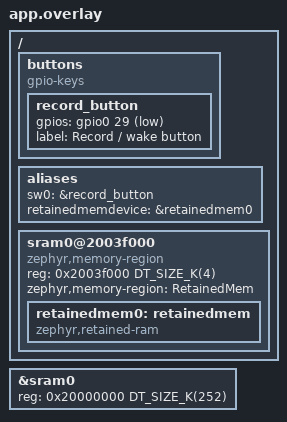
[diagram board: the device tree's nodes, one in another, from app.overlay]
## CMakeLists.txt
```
cmake_minimum_required(VERSION 3.20.0)

set(COMMON_DIR ${CMAKE_CURRENT_SOURCE_DIR}/../common)
list(APPEND DTS_ROOT ${COMMON_DIR})

find_package(Zephyr REQUIRED HINTS $ENV{ZEPHYR_BASE})
project(sus_recorder)

target_include_directories(app PRIVATE
	${COMMON_DIR}/src
	${CMAKE_CURRENT_SOURCE_DIR}/src
)

target_sources(app PRIVATE
	${COMMON_DIR}/src/as5600.c
	${COMMON_DIR}/src/battery.c
	${COMMON_DIR}/src/board_power.c
	${COMMON_DIR}/src/flash.c
	${COMMON_DIR}/src/flash_zephyr.c
	${COMMON_DIR}/src/sensor_reader.c
	src/flash_serial.c
	src/log_id_retention.c
	src/main.c
	src/status_led.c
)

target_compile_options(app PRIVATE
	-Wextra
	-Werror
)
```

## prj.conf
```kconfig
CONFIG_GPIO=y
CONFIG_ADC=y
CONFIG_I2C=y
CONFIG_I2C_NRFX_TRANSFER_TIMEOUT=2
CONFIG_SPI=y
CONFIG_FLASH=y
CONFIG_SPI_NOR=y
CONFIG_SPI_NOR_SFDP_RUNTIME=y
CONFIG_FLASH_JESD216_API=y
CONFIG_SPI_NOR_FLASH_LAYOUT_PAGE_SIZE=4096
CONFIG_SENSOR=y

CONFIG_LSM6DSO=y
CONFIG_LSM6DSO_ENABLE_TEMP=y
CONFIG_LSM6DSO_TRIGGER_NONE=y

CONFIG_MMC56X3=y

CONFIG_LIS3MDL=y
CONFIG_LIS3MDL_ODR="155"
CONFIG_LIS3MDL_FS=8
CONFIG_LIS3MDL_TRIGGER_NONE=y

CONFIG_RETAINED_MEM=y
CONFIG_CRC=y
CONFIG_POWEROFF=y
CONFIG_PM_DEVICE=y

CONFIG_PRINTK=y
CONFIG_SERIAL=y
CONFIG_UART_INTERRUPT_DRIVEN=y
CONFIG_CONSOLE=y
CONFIG_UART_CONSOLE=y

CONFIG_MAIN_STACK_SIZE=3072
CONFIG_MAIN_THREAD_PRIORITY=5
CONFIG_ASSERT=y
```

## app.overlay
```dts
#include "../common/sus_board.dtsi"

/ {
	buttons {
		compatible = "gpio-keys";

		record_button: record_button {
			/* XIAO D3 = nRF P0.29; normally open, pressed connects to ground. */
			gpios = <&gpio0 29 (GPIO_PULL_UP | GPIO_ACTIVE_LOW)>;
			label = "Record / wake button";
		};
	};

	aliases {
		sw0 = &record_button;
		retainedmemdevice = &retainedmem0;
	};

	/*
	 * Retain one 4 KiB nRF52840 RAM section across System OFF. The normal
	 * SRAM node below is shortened so the linker cannot use this region.
	 */
	sram0@2003f000 {
		compatible = "zephyr,memory-region", "mmio-sram";
		reg = <0x2003f000 DT_SIZE_K(4)>;
		zephyr,memory-region = "RetainedMem";
		status = "okay";

		retainedmem0: retainedmem {
			compatible = "zephyr,retained-ram";
			status = "okay";
		};
	};
};

&sram0 {
	reg = <0x20000000 DT_SIZE_K(252)>;
};
```

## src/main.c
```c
#include <errno.h>
#include <stdbool.h>
#include <stddef.h>
#include <stdint.h>
#include <string.h>

#include <zephyr/device.h>
#include <zephyr/devicetree.h>
#include <zephyr/drivers/gpio.h>
#include <zephyr/drivers/usb/udc.h>
#include <zephyr/kernel.h>
#include <zephyr/pm/device.h>
#include <zephyr/sys/atomic.h>
#include <zephyr/sys/poweroff.h>
#include <zephyr/sys/printk.h>
#include <zephyr/sys/util.h>

#include "as5600.h"
#include "battery.h"
#include "board_power.h"
#include "flash.h"
#include "flash_serial.h"
#include "flash_zephyr.h"
#include "log_id_retention.h"
#include "log_record.h"
#include "sensor_reader.h"
#include "status_led.h"

#define SAMPLE_INTERVAL_MS 5U
#define BUTTON_POLL_MS 20U
#define BUTTON_DEBOUNCE_MS 50U
#define BUTTON_LONG_PRESS_MS 800U
#define UPLOAD_HELLO_WINDOW_MS 5000U
#define RECORD_QUEUE_DEPTH 128U
#define FLASH_SCAN_STATUS_INTERVAL_SECTORS 256U
#define FLASH_SCAN_STATUS_INTERVAL_MS 5000U
#define REQUIRED_SENSOR_MASK \
	(SUS_SENSOR_IMU1 | SUS_SENSOR_IMU2 | SUS_SENSOR_MMC5603)
#define RECORDS_PER_SECTOR \
	(FLASH_LOG_PAYLOAD_BYTES / sizeof(struct sus_log_record))

BUILD_ASSERT(RECORDS_PER_SECTOR == 81U);

K_MSGQ_DEFINE(record_queue, sizeof(struct sus_log_record),
	      RECORD_QUEUE_DEPTH, 4);
K_SEM_DEFINE(sampler_stopped, 0, 1);

static const struct gpio_dt_spec record_button =
	GPIO_DT_SPEC_GET(DT_ALIAS(sw0), gpios);
static const struct device *const usb_controller =
	DEVICE_DT_GET(DT_NODELABEL(zephyr_udc0));
static const struct device *const serial_uart =
	DEVICE_DT_GET(DT_CHOSEN(zephyr_console));

static struct sus_sensor_reader sensor_reader;
static struct sus_as5600 angle_sensor;
static atomic_t stop_requested;
static atomic_t dropped_records;
static atomic_t missed_deadlines;
static atomic_t angle_read_errors;
static atomic_t sensor_fault_detected;
static bool record_button_ready;

struct flash_scan_status {
	int64_t started_ms;
	int64_t last_report_ms;
	uint32_t erased_sectors;
	bool erase_pending;
};

static void flash_scan_progress(void *context,
				enum flash_log_scan_phase phase,
				uint32_t completed_sectors,
				uint32_t total_sectors)
{
	struct flash_scan_status *status = context;
	int64_t now = k_uptime_get();
	uint32_t elapsed_seconds;
	uint32_t percent;
	bool report_due;

	if (phase == FLASH_LOG_SCAN_CLEANUP_ERASE) {
		status->erase_pending = true;
		if (status->erased_sectors != 0U &&
		    now - status->last_report_ms <
			    FLASH_SCAN_STATUS_INTERVAL_MS) {
			return;
		}
		elapsed_seconds = (uint32_t)((now - status->started_ms) /
					     1000);
		printk("Flash scan cleanup: starting erase %u after "
		       "%u/%u inspected, elapsed=%u s\n",
		       status->erased_sectors + 1U, completed_sectors,
		       total_sectors, elapsed_seconds);
		status->last_report_ms = now;
		return;
	}

	if (phase == FLASH_LOG_SCAN_CLEANUP && status->erase_pending) {
		status->erased_sectors++;
		status->erase_pending = false;
	}
	if (completed_sectors == 0U || total_sectors == 0U) {
		return;
	}

	report_due = completed_sectors == total_sectors ||
		     (completed_sectors %
		      FLASH_SCAN_STATUS_INTERVAL_SECTORS) == 0U ||
		     now - status->last_report_ms >=
			     FLASH_SCAN_STATUS_INTERVAL_MS;
	if (!report_due) {
		return;
	}

	elapsed_seconds = (uint32_t)((now - status->started_ms) / 1000);
	percent = (completed_sectors * 100U) / total_sectors;
	if (phase == FLASH_LOG_SCAN_DISCOVER) {
		printk("Flash scan discover: %u/%u inspected (%u%%), "
		       "elapsed=%u s\n",
		       completed_sectors, total_sectors, percent,
		       elapsed_seconds);
	} else {
		printk("Flash scan cleanup: %u/%u inspected (%u%%), "
		       "erased=%u, elapsed=%u s\n",
		       completed_sectors, total_sectors, percent,
		       status->erased_sectors, elapsed_seconds);
	}
	status->last_report_ms = now;
}

static void make_record(struct sus_log_record *record)
{
	struct sus_sensor_sample sample;
	uint16_t angle;

	sus_sensor_reader_read(&sensor_reader, &sample);
	if ((sample.valid & REQUIRED_SENSOR_MASK) != REQUIRED_SENSOR_MASK) {
		atomic_set(&sensor_fault_detected, 1);
	}
	memset(record, 0, sizeof(*record));
	record->timestamp_ms = sample.timestamp_ms;
	record->sequence = sample.sequence;
	memcpy(record->imu1_accel_mg, sample.imu1.accel_mg,
	       sizeof(record->imu1_accel_mg));
	memcpy(record->imu2_accel_mg, sample.imu2.accel_mg,
	       sizeof(record->imu2_accel_mg));
	memcpy(record->imu1_gyro_dps10, sample.imu1.gyro_dps10,
	       sizeof(record->imu1_gyro_dps10));
	memcpy(record->imu2_gyro_dps10, sample.imu2.gyro_dps10,
	       sizeof(record->imu2_gyro_dps10));
	memcpy(record->mmc5603_mg, sample.mmc5603_mg,
	       sizeof(record->mmc5603_mg));
	memcpy(record->lis3mdl_mg, sample.lis3mdl_mg,
	       sizeof(record->lis3mdl_mg));
	record->temp_deci_c = sample.imu1.temp_deci_c;

	if (sus_as5600_read(&angle_sensor, &angle) != 0) {
		atomic_inc(&angle_read_errors);
		atomic_set(&sensor_fault_detected, 1);
	} else {
		record->angle = angle;
	}
}

static void sampler_thread(void *unused1, void *unused2, void *unused3)
{
	int64_t deadline = k_uptime_get();

	ARG_UNUSED(unused1);
	ARG_UNUSED(unused2);
	ARG_UNUSED(unused3);

	while (atomic_get(&stop_requested) == 0) {
		struct sus_log_record record;
		int64_t now;

		deadline += SAMPLE_INTERVAL_MS;
		k_sleep(K_TIMEOUT_ABS_MS(deadline));
		if (atomic_get(&stop_requested) != 0) {
			break;
		}

		make_record(&record);
		if (k_msgq_put(&record_queue, &record, K_NO_WAIT) != 0) {
			atomic_inc(&dropped_records);
		}

		now = k_uptime_get();
		if (now >= deadline + SAMPLE_INTERVAL_MS) {
			int64_t skipped =
				(now - deadline) / SAMPLE_INTERVAL_MS;

			deadline += skipped * SAMPLE_INTERVAL_MS;
			atomic_add(&missed_deadlines, (atomic_val_t)skipped);
		}
	}

	k_sem_give(&sampler_stopped);
}

static void button_thread(void *unused1, void *unused2, void *unused3)
{
	int64_t pressed_at = 0;

	ARG_UNUSED(unused1);
	ARG_UNUSED(unused2);
	ARG_UNUSED(unused3);

	/* Do not count the button press that woke the board as a stop press. */
	while (gpio_pin_get_dt(&record_button) > 0) {
		k_msleep(BUTTON_POLL_MS);
	}
	k_msleep(BUTTON_DEBOUNCE_MS);

	while (atomic_get(&stop_requested) == 0) {
		int pressed = gpio_pin_get_dt(&record_button);

		if (pressed > 0) {
			if (pressed_at == 0) {
				pressed_at = k_uptime_get();
			} else if (k_uptime_get() - pressed_at >=
				   BUTTON_LONG_PRESS_MS) {
				atomic_set(&stop_requested, 1);
				status_led_set(STATUS_LED_OFF);
				printk("Long press: stopping recording\n");
				break;
			}
		} else {
			pressed_at = 0;
		}
		k_msleep(BUTTON_POLL_MS);
	}
}

K_THREAD_DEFINE(sampler_thread_id, 3072, sampler_thread,
		NULL, NULL, NULL, 1, 0, SYS_FOREVER_MS);
K_THREAD_DEFINE(button_thread_id, 1024, button_thread,
		NULL, NULL, NULL, 2, 0, SYS_FOREVER_MS);

struct record_accumulator {
	struct sus_log_record records[RECORDS_PER_SECTOR];
	size_t count;
};

static enum flash_log_result
flush_records(struct flash_log *log, struct record_accumulator *accumulator,
	      uint32_t *written_records)
{
	enum flash_log_result result;

	if (accumulator->count == 0U) {
		return FLASH_LOG_OK;
	}

	result = flash_log_append(
		log, accumulator->records,
		accumulator->count * sizeof(accumulator->records[0]));
	if (result == FLASH_LOG_OK) {
		*written_records += (uint32_t)accumulator->count;
		accumulator->count = 0U;
	}
	return result;
}

static enum flash_log_result
queue_record(struct flash_log *log, struct record_accumulator *accumulator,
	     const struct sus_log_record *record, uint32_t *written_records)
{
	accumulator->records[accumulator->count++] = *record;
	if (accumulator->count == ARRAY_SIZE(accumulator->records)) {
		return flush_records(log, accumulator, written_records);
	}
	return FLASH_LOG_OK;
}

static void wait_for_button_release(void)
{
	while (gpio_pin_get_dt(&record_button) > 0) {
		k_msleep(BUTTON_POLL_MS);
	}
	k_msleep(BUTTON_DEBOUNCE_MS);
}

static void enter_system_off(struct flash_zephyr_storage *storage)
{
	int err;

	if (!record_button_ready) {
		printk("Cannot enter System OFF without a configured wake button\n");
		return;
	}

	if (storage != NULL && storage->device != NULL) {
		err = pm_device_action_run(storage->device,
					   PM_DEVICE_ACTION_SUSPEND);
		if (err != 0 && err != -EALREADY) {
			printk("Flash deep-power-down failed: %d\n", err);
		}
		k_msleep(1);
	}

	err = board_peripheral_power_set_enabled(false);
	if (err != 0) {
		printk("Peripheral rail shutdown failed: %d\n", err);
	}

	/* Hardware is quiescent; only now wait for a clean wake-button edge. */
	wait_for_button_release();

	err = gpio_pin_interrupt_configure_dt(&record_button,
					      GPIO_INT_LEVEL_ACTIVE);
	if (err != 0) {
		printk("Button wake configuration failed: %d\n", err);
		return;
	}

	printk("Entering System OFF; press D3 to record again\n");
	k_msleep(10);

	if (device_is_ready(usb_controller)) {
		(void)udc_disable(usb_controller);
	}
	status_led_set(STATUS_LED_OFF);
	sys_poweroff();
}

static void indicate_error(void)
{
	status_led_set(STATUS_LED_RED);
	/* Keep fatal errors visible before System OFF removes LED power. */
	k_msleep(1500);
}

static int retain_log_state(const struct flash_log *log, bool clean)
{
	struct flash_log_checkpoint checkpoint;

	flash_log_checkpoint_save(log, &checkpoint);
	return log_id_retention_store(&checkpoint, clean);
}

static int recorder_hardware_init(void)
{
	int err;

	if (!gpio_is_ready_dt(&record_button)) {
		return -ENODEV;
	}

	err = gpio_pin_configure_dt(&record_button, GPIO_INPUT);
	if (err != 0) {
		return err;
	}
	record_button_ready = true;
	if (!board_peripheral_power_is_ready()) {
		return -ENODEV;
	}

	sus_sensor_reader_init(&sensor_reader);
	err = sus_as5600_init(&angle_sensor);
	if (err != 0) {
		printk("AS5600 not available: %d; angle will be zero\n", err);
	}

	printk("Sensors: IMU1=%s IMU2=%s MMC5603=%s LIS3MDL=%s "
	       "AS5600=%s\n",
	       (sensor_reader.available & SUS_SENSOR_IMU1) != 0U ?
		       "yes" : "no",
	       (sensor_reader.available & SUS_SENSOR_IMU2) != 0U ?
		       "yes" : "no",
	       (sensor_reader.available & SUS_SENSOR_MMC5603) != 0U ?
		       "yes" : "no",
	       (sensor_reader.available & SUS_SENSOR_LIS3MDL) != 0U ?
		       "yes" : "no",
	       angle_sensor.available ? "yes" : "no");
	return 0;
}

int main(void)
{
	static struct flash_zephyr_storage storage;
	static struct flash_chunk scratch;
	static struct flash_log log;
	static struct flash_serial_transport serial_transport;
	static struct record_accumulator accumulator;
	struct sus_log_record record;
	struct retained_log_state retained_state;
	struct flash_scan_status scan_status;
	enum flash_log_result log_result;
	uint32_t active_log_id = 0;
	uint32_t written_records = 0;
	int64_t next_status_ms;
	enum flash_serial_session_result upload_result;
	const struct flash_transport_ops *transport_ops = NULL;
	void *transport_context = NULL;
	bool writer_ok = true;
	bool serial_ready = false;
	bool retained_state_available = false;
	bool checkpoint_restored = false;
	bool recording_error = false;
	int32_t battery_mv;
	int err;

	printk("\nSUS 200 Hz recorder starting\n");
	err = sus_battery_init();
	if (err != 0) {
		printk("Battery monitor initialization failed: %d\n", err);
	} else {
		err = sus_battery_read_mv(&battery_mv);
		if (err != 0) {
			printk("Battery voltage read failed: %d\n", err);
		} else {
			printk("Battery: %d mV\n", battery_mv);
		}
	}
	err = status_led_init();
	if (err != 0) {
		printk("Status LED unavailable: %d\n", err);
	} else {
		status_led_set(STATUS_LED_WHITE);
	}

	err = recorder_hardware_init();
	if (err != 0) {
		printk("Hardware initialization failed: %d\n", err);
		indicate_error();
		enter_system_off(NULL);
		return 0;
	}

	err = flash_zephyr_storage_init_default(&storage);
	if (err != 0) {
		printk("Flash initialization failed: %d\n", err);
		indicate_error();
		enter_system_off(&storage);
		return 0;
	}

	err = flash_serial_transport_init(
		&serial_transport, serial_uart, storage.sector_count);
	if (err == 0) {
		transport_ops = &flash_serial_transport_ops;
		transport_context = &serial_transport;
		serial_ready = true;
	} else {
		printk("USB log upload unavailable: %d\n", err);
	}

	log_result = flash_log_init(
		&log, storage.sector_count, &scratch,
		&flash_zephyr_storage_ops, &storage, transport_ops,
		transport_context);
	if (log_result != FLASH_LOG_OK) {
		printk("Flash log initialization failed: %d\n", log_result);
		indicate_error();
		enter_system_off(&storage);
		return 0;
	}

	err = log_id_retention_load(&retained_state);
	if (err == 0) {
		retained_state_available = true;
		if (retained_state.clean) {
			log_result = flash_log_checkpoint_restore(
				&log, &retained_state.checkpoint);
			if (log_result == FLASH_LOG_OK) {
				checkpoint_restored = true;
				printk("Restored flash checkpoint: read=%u "
				       "write=%u next_log=%u\n",
				       log.read_sector, log.write_sector,
				       log.next_log_id);
			} else {
				printk("Retained flash checkpoint rejected: %d\n",
				       log_result);
			}
		} else {
			printk("Retained flash checkpoint is dirty; "
			       "full scan required\n");
		}
	} else {
		printk("Retained flash checkpoint unavailable: %d; "
		       "full scan required\n", err);
	}

	if (!checkpoint_restored) {
		status_led_set(STATUS_LED_PURPLE);
		scan_status = (struct flash_scan_status) {
			.started_ms = k_uptime_get(),
			.last_report_ms = k_uptime_get(),
		};
		printk("Scanning %u flash sectors...\n", log.sector_count);
		log_result = flash_log_scan_with_progress(
			&log, flash_scan_progress, &scan_status);
		if (log_result != FLASH_LOG_OK) {
			printk("Flash scan failed: %d\n", log_result);
			indicate_error();
			enter_system_off(&storage);
			return 0;
		}

		if (flash_log_is_empty(&log) && retained_state_available) {
			log.next_log_id =
				retained_state.checkpoint.next_log_id;
			printk("Restored next log ID %u from retained RAM\n",
			       log.next_log_id);
		} else if (!flash_log_is_empty(&log)) {
			printk("Recovered next log ID %u from flash\n",
			       log.next_log_id);
		} else {
			printk("No retained log ID; starting at %u\n",
			       log.next_log_id);
		}
	}

	/* Any flash mutation makes these pointers unsafe until re-checkpointed. */
	err = retain_log_state(&log, false);
	if (err != 0) {
		printk("Could not invalidate retained flash checkpoint: %d\n",
		       err);
		indicate_error();
		enter_system_off(&storage);
		return 0;
	}

	if (serial_ready) {
		status_led_set(STATUS_LED_BLUE);
		printk("Waiting %u ms for a USB log receiver...\n",
		       UPLOAD_HELLO_WINDOW_MS);
		upload_result = flash_serial_upload_session(
			&serial_transport, &log,
			UPLOAD_HELLO_WINDOW_MS);
		if (upload_result != FLASH_SERIAL_NO_HOST) {
			if (upload_result == FLASH_SERIAL_SESSION_COMPLETE) {
				err = retain_log_state(&log, true);
				if (err != 0) {
					printk("Post-upload checkpoint failed: %d\n",
					       err);
					indicate_error();
				}
			} else {
				indicate_error();
			}
			printk("USB upload session %s; powering down\n",
			       upload_result ==
					       FLASH_SERIAL_SESSION_COMPLETE ?
				       "complete" : "failed");
			enter_system_off(&storage);
			return 0;
		}
	}

	log_result = flash_log_begin(&log, &active_log_id);
	if (log_result != FLASH_LOG_OK) {
		printk("Could not begin log: %d\n", log_result);
		indicate_error();
		enter_system_off(&storage);
		return 0;
	}

	printk("Recording log %u at 200 Hz; hold D3 for 0.8 s to stop\n",
	       active_log_id);
	if ((sensor_reader.available & REQUIRED_SENSOR_MASK) ==
			REQUIRED_SENSOR_MASK && angle_sensor.available) {
		status_led_set(STATUS_LED_GREEN);
	} else {
		atomic_set(&sensor_fault_detected, 1);
		status_led_set(STATUS_LED_YELLOW);
	}
	k_thread_start(sampler_thread_id);
	k_thread_start(button_thread_id);
	next_status_ms = k_uptime_get() + 1000;

	while (atomic_get(&stop_requested) == 0) {
		if (k_msgq_get(&record_queue, &record, K_MSEC(100)) == 0) {
			log_result = queue_record(
				&log, &accumulator, &record,
				&written_records);
			if (log_result != FLASH_LOG_OK) {
				printk("Flash append stopped: %d\n",
				       log_result);
				status_led_set(STATUS_LED_RED);
				recording_error = true;
				writer_ok = false;
				atomic_set(&stop_requested, 1);
				break;
			}
		}

		if (k_uptime_get() >= next_status_ms) {
			if ((atomic_get(&sensor_fault_detected) != 0 ||
			     atomic_get(&dropped_records) != 0 ||
			     atomic_get(&missed_deadlines) != 0) && writer_ok) {
				status_led_set(STATUS_LED_YELLOW);
			}
			printk("log=%u records=%u queued=%u dropped=%ld "
			       "missed=%ld\n",
			       active_log_id, written_records,
			       k_msgq_num_used_get(&record_queue),
			       (long)atomic_get(&dropped_records),
			       (long)atomic_get(&missed_deadlines));
			next_status_ms += 1000;
		}
	}

	k_sem_take(&sampler_stopped, K_FOREVER);
	while (k_msgq_get(&record_queue, &record, K_NO_WAIT) == 0) {
		if (writer_ok) {
			log_result = queue_record(
				&log, &accumulator, &record,
				&written_records);
			if (log_result != FLASH_LOG_OK) {
				printk("Final flash append failed: %d\n",
				       log_result);
				status_led_set(STATUS_LED_RED);
				recording_error = true;
				writer_ok = false;
			}
		}
	}

	if (writer_ok) {
		log_result = flush_records(&log, &accumulator,
					   &written_records);
		if (log_result != FLASH_LOG_OK) {
			printk("Partial-sector write failed: %d\n",
			       log_result);
			status_led_set(STATUS_LED_RED);
			recording_error = true;
			writer_ok = false;
		}
	}

	log_result = flash_log_close(&log);
	if (log_result != FLASH_LOG_OK) {
		status_led_set(STATUS_LED_RED);
		recording_error = true;
		printk("Commit write failed: %d; boot recovery will retain "
		       "the valid prefix\n", log_result);
	} else {
		printk("Closed log %u: %u records, dropped=%ld, "
		       "missed=%ld, angle_errors=%ld%s\n",
		       active_log_id, written_records,
		       (long)atomic_get(&dropped_records),
		       (long)atomic_get(&missed_deadlines),
		       (long)atomic_get(&angle_read_errors),
		       writer_ok ? "" : " (recording stopped early)");
	}

	if (log_result == FLASH_LOG_OK) {
		err = retain_log_state(&log, true);
		if (err != 0) {
			printk("Final flash checkpoint failed: %d\n", err);
			status_led_set(STATUS_LED_RED);
			recording_error = true;
		}
	}

	if (recording_error) {
		indicate_error();
	}
	enter_system_off(&storage);
	return 0;
}
```

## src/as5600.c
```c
#include "as5600.h"

#include <errno.h>
#include <stdint.h>

#include <zephyr/device.h>
#include <zephyr/devicetree.h>
#include <zephyr/drivers/i2c.h>

#define AS5600_ADDRESS 0x36U
#define AS5600_ZPOS_REGISTER 0x01U
#define AS5600_MPOS_REGISTER 0x03U
#define AS5600_MANG_REGISTER 0x05U
#define AS5600_CONF_REGISTER 0x07U
#define AS5600_STATUS_REGISTER 0x0bU
#define AS5600_ANGLE_REGISTER 0x0eU

#define AS5600_CONF_HIGH 0x06U
#define AS5600_CONF_LOW 0x20U

static const struct device *const sensor_i2c =
	DEVICE_DT_GET(DT_BUS(DT_ALIAS(imu1)));

static int as5600_write_u12(uint8_t reg, uint16_t value)
{
	const uint8_t bytes[2] = {
		(uint8_t)((value >> 8U) & 0x0fU),
		(uint8_t)value,
	};

	return i2c_burst_write(sensor_i2c, AS5600_ADDRESS, reg, bytes,
			       sizeof(bytes));
}

int sus_as5600_init(struct sus_as5600 *sensor)
{
	uint8_t status;
	const uint8_t config[2] = {
		AS5600_CONF_HIGH,
		AS5600_CONF_LOW,
	};
	int err;

	if (sensor == NULL || !device_is_ready(sensor_i2c)) {
		return -ENODEV;
	}

	sensor->i2c = sensor_i2c;
	sensor->available = false;

	err = i2c_reg_read_byte(sensor->i2c, AS5600_ADDRESS,
				AS5600_STATUS_REGISTER, &status);
	if (err != 0) {
		return err;
	}

	/*
	 * Match the ESP configuration: normal power, no hysteresis, digital
	 * PWM output, 4x slow filter, 6-LSB fast-filter threshold, watchdog
	 * off, and the full 12-bit angular range.
	 */
	err = i2c_burst_write(sensor->i2c, AS5600_ADDRESS,
			      AS5600_CONF_REGISTER, config,
			      sizeof(config));
	if (err == 0) {
		err = as5600_write_u12(AS5600_ZPOS_REGISTER, 0U);
	}
	if (err == 0) {
		err = as5600_write_u12(AS5600_MPOS_REGISTER, 4095U);
	}
	if (err == 0) {
		err = as5600_write_u12(AS5600_MANG_REGISTER, 4095U);
	}
	if (err != 0) {
		return err;
	}

	sensor->available = true;
	return 0;
}

int sus_as5600_read(const struct sus_as5600 *sensor, uint16_t *angle)
{
	uint8_t bytes[2];
	int err;

	if (sensor == NULL || angle == NULL || !sensor->available) {
		return -ENODEV;
	}

	err = i2c_burst_read(sensor->i2c, AS5600_ADDRESS,
			     AS5600_ANGLE_REGISTER, bytes, sizeof(bytes));
	if (err != 0) {
		return err;
	}

	*angle = (((uint16_t)bytes[0] << 8U) | bytes[1]) & 0x0fffU;
	return 0;
}
```

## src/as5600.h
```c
#ifndef SUS_AS5600_H_
#define SUS_AS5600_H_

#include <stdbool.h>
#include <stdint.h>

#include <zephyr/device.h>

struct sus_as5600 {
	const struct device *i2c;
	bool available;
};

int sus_as5600_init(struct sus_as5600 *sensor);
int sus_as5600_read(const struct sus_as5600 *sensor, uint16_t *angle);

#endif /* SUS_AS5600_H_ */
```

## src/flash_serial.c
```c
#include "flash_serial.h"

#include <errno.h>
#include <stdbool.h>
#include <stddef.h>
#include <stdint.h>
#include <string.h>

#include <zephyr/drivers/uart.h>
#include <zephyr/kernel.h>
#include <zephyr/sys/crc.h>

#define FLASH_SERIAL_MAGIC UINT32_C(0x50535553)
#define FLASH_SERIAL_HEADER_BYTES 12U
#define FLASH_SERIAL_CRC_BYTES 4U
#define FLASH_SERIAL_FRAME_TIMEOUT_MS 10000U

enum flash_serial_message {
	FLASH_SERIAL_HELLO = 1,
	FLASH_SERIAL_INFO = 2,
	FLASH_SERIAL_READ_NEXT = 3,
	FLASH_SERIAL_BEGIN = 4,
	FLASH_SERIAL_SECTOR = 5,
	FLASH_SERIAL_SECTOR_ACK = 6,
	FLASH_SERIAL_END = 7,
	FLASH_SERIAL_DISPOSITION = 8,
	FLASH_SERIAL_EMPTY = 9,
	FLASH_SERIAL_SESSION_DONE = 10,
	FLASH_SERIAL_ERROR = 11,
	FLASH_SERIAL_ERASE_COMPLETE = 12,
};

enum flash_serial_disposition {
	FLASH_SERIAL_DISPOSITION_ERASE = 1,
	FLASH_SERIAL_DISPOSITION_RETRY = 2,
	FLASH_SERIAL_DISPOSITION_DONE = 3,
};

struct flash_serial_frame {
	uint8_t type;
	uint32_t token;
	const uint8_t *payload;
	uint16_t payload_length;
};

static void store_u16_le(uint8_t output[2], uint16_t value)
{
	output[0] = (uint8_t)value;
	output[1] = (uint8_t)(value >> 8U);
}

static void store_u32_le(uint8_t output[4], uint32_t value)
{
	output[0] = (uint8_t)value;
	output[1] = (uint8_t)(value >> 8U);
	output[2] = (uint8_t)(value >> 16U);
	output[3] = (uint8_t)(value >> 24U);
}

static uint16_t load_u16_le(const uint8_t input[2])
{
	return (uint16_t)input[0] | ((uint16_t)input[1] << 8U);
}

static uint32_t load_u32_le(const uint8_t input[4])
{
	return (uint32_t)input[0] | ((uint32_t)input[1] << 8U) |
	       ((uint32_t)input[2] << 16U) |
	       ((uint32_t)input[3] << 24U);
}

static size_t cobs_encode(const uint8_t *input, size_t input_length,
			  uint8_t *output, size_t output_capacity)
{
	size_t read_index = 0;
	size_t write_index = 1;
	size_t code_index = 0;
	uint8_t code = 1;

	if (output_capacity == 0U) {
		return 0;
	}

	while (read_index < input_length) {
		if (input[read_index] == 0U) {
			if (code_index >= output_capacity) {
				return 0;
			}
			output[code_index] = code;
			code = 1;
			code_index = write_index++;
			if (write_index > output_capacity) {
				return 0;
			}
			read_index++;
			continue;
		}

		if (write_index >= output_capacity) {
			return 0;
		}
		output[write_index++] = input[read_index++];
		code++;
		if (code == UINT8_MAX) {
			if (code_index >= output_capacity) {
				return 0;
			}
			output[code_index] = code;
			code = 1;
			code_index = write_index++;
			if (write_index > output_capacity) {
				return 0;
			}
		}
	}

	if (code_index >= output_capacity) {
		return 0;
	}
	output[code_index] = code;
	return write_index;
}

static size_t cobs_decode_in_place(uint8_t *buffer, size_t encoded_length)
{
	size_t read_index = 0;
	size_t write_index = 0;

	while (read_index < encoded_length) {
		uint8_t code = buffer[read_index++];
		size_t copy_length;

		if (code == 0U) {
			return 0;
		}
		copy_length = (size_t)code - 1U;
		if (read_index + copy_length > encoded_length) {
			return 0;
		}
		for (size_t i = 0; i < copy_length; i++) {
			buffer[write_index++] = buffer[read_index++];
		}
		if (code != UINT8_MAX && read_index < encoded_length) {
			buffer[write_index++] = 0U;
		}
	}

	return write_index;
}

static void serial_uart_callback(const struct device *uart, void *user_data)
{
	struct flash_serial_transport *transport = user_data;
	unsigned char byte;

	if (uart_irq_update(uart) <= 0) {
		return;
	}

	while (uart_irq_rx_ready(uart)) {
		if (uart_fifo_read(uart, &byte, 1) <= 0) {
			break;
		}
		if (k_msgq_put(&transport->rx_queue, &byte, K_NO_WAIT) != 0) {
			atomic_set(&transport->rx_overflow, 1);
		}
	}

	if (!uart_irq_tx_ready(uart) ||
	    atomic_get(&transport->tx_active) == 0) {
		return;
	}

	while (transport->tx_offset < transport->tx_length) {
		size_t remaining =
			transport->tx_length - transport->tx_offset;
		int written = uart_fifo_fill(
			uart, &transport->tx_data[transport->tx_offset],
			(int)remaining);

		if (written <= 0) {
			break;
		}
		transport->tx_offset += (size_t)written;
	}

	if (transport->tx_offset == transport->tx_length &&
	    atomic_cas(&transport->tx_active, 1, 0)) {
		uart_irq_tx_disable(uart);
		k_sem_give(&transport->tx_done);
	}
}

static int send_encoded(struct flash_serial_transport *transport,
			size_t encoded_length)
{
	k_sem_reset(&transport->tx_done);
	transport->tx_data = transport->encoded;
	transport->tx_length = encoded_length;
	transport->tx_offset = 0;
	atomic_set(&transport->tx_active, 1);
	uart_irq_tx_enable(transport->uart);

	if (k_sem_take(&transport->tx_done,
		       K_MSEC(FLASH_SERIAL_FRAME_TIMEOUT_MS)) != 0) {
		atomic_clear(&transport->tx_active);
		uart_irq_tx_disable(transport->uart);
		return -ETIMEDOUT;
	}
	return 0;
}

static int send_frame(struct flash_serial_transport *transport,
		      uint8_t type, uint32_t token,
		      const void *payload, uint16_t payload_length)
{
	size_t decoded_length = FLASH_SERIAL_HEADER_BYTES +
				(size_t)payload_length +
				FLASH_SERIAL_CRC_BYTES;
	size_t encoded_length;
	uint32_t crc;

	if (transport == NULL || transport->uart == NULL ||
	    decoded_length > sizeof(transport->decoded) ||
	    (payload_length != 0U && payload == NULL)) {
		return -EINVAL;
	}

	store_u32_le(&transport->decoded[0], FLASH_SERIAL_MAGIC);
	transport->decoded[4] = FLASH_SERIAL_PROTOCOL_VERSION;
	transport->decoded[5] = type;
	store_u16_le(&transport->decoded[6], payload_length);
	store_u32_le(&transport->decoded[8], token);
	if (payload_length != 0U) {
		memcpy(&transport->decoded[FLASH_SERIAL_HEADER_BYTES],
		       payload, payload_length);
	}
	crc = crc32_ieee(transport->decoded,
			 decoded_length - FLASH_SERIAL_CRC_BYTES);
	store_u32_le(&transport->decoded[
			     decoded_length - FLASH_SERIAL_CRC_BYTES],
		     crc);

	transport->encoded[0] = 0U;
	encoded_length = cobs_encode(
		transport->decoded, decoded_length,
		&transport->encoded[1],
		sizeof(transport->encoded) - 2U);
	if (encoded_length == 0U) {
		return -EMSGSIZE;
	}
	transport->encoded[encoded_length + 1U] = 0U;
	return send_encoded(transport, encoded_length + 2U);
}

static bool parse_frame(struct flash_serial_transport *transport,
			size_t encoded_length,
			struct flash_serial_frame *frame)
{
	size_t decoded_length =
		cobs_decode_in_place(transport->encoded, encoded_length);
	uint16_t payload_length;
	uint32_t expected_crc;
	uint32_t actual_crc;

	if (decoded_length <
	    FLASH_SERIAL_HEADER_BYTES + FLASH_SERIAL_CRC_BYTES) {
		return false;
	}
	payload_length = load_u16_le(&transport->encoded[6]);
	if (decoded_length != FLASH_SERIAL_HEADER_BYTES +
				      (size_t)payload_length +
				      FLASH_SERIAL_CRC_BYTES ||
	    load_u32_le(&transport->encoded[0]) !=
		    FLASH_SERIAL_MAGIC ||
	    transport->encoded[4] != FLASH_SERIAL_PROTOCOL_VERSION) {
		return false;
	}

	expected_crc = load_u32_le(
		&transport->encoded[decoded_length -
				    FLASH_SERIAL_CRC_BYTES]);
	actual_crc = crc32_ieee(
		transport->encoded,
		decoded_length - FLASH_SERIAL_CRC_BYTES);
	if (actual_crc != expected_crc) {
		return false;
	}

	frame->type = transport->encoded[5];
	frame->token = load_u32_le(&transport->encoded[8]);
	frame->payload = &transport->encoded[FLASH_SERIAL_HEADER_BYTES];
	frame->payload_length = payload_length;
	return true;
}

static int receive_frame(struct flash_serial_transport *transport,
			 uint32_t timeout_ms,
			 struct flash_serial_frame *frame)
{
	int64_t deadline = k_uptime_get() + timeout_ms;
	size_t encoded_length = 0;
	bool overflow = false;

	while (k_uptime_get() < deadline) {
		unsigned char byte;

		if (atomic_cas(&transport->rx_overflow, 1, 0)) {
			encoded_length = 0;
			overflow = true;
		}
		if (k_msgq_get(&transport->rx_queue, &byte, K_MSEC(1)) != 0) {
			continue;
		}
		if (byte != 0U) {
			if (!overflow &&
			    encoded_length < sizeof(transport->encoded)) {
				transport->encoded[encoded_length++] = byte;
			} else {
				overflow = true;
			}
			continue;
		}
		if (encoded_length == 0U && !overflow) {
			continue;
		}
		if (!overflow &&
		    parse_frame(transport, encoded_length, frame)) {
			return 0;
		}
		encoded_length = 0;
		overflow = false;
	}

	return -ETIMEDOUT;
}

static int wait_for_frame(struct flash_serial_transport *transport,
			  uint8_t expected_type, uint32_t expected_token,
			  uint32_t timeout_ms,
			  struct flash_serial_frame *frame)
{
	int64_t deadline = k_uptime_get() + timeout_ms;

	while (k_uptime_get() < deadline) {
		uint32_t remaining =
			(uint32_t)(deadline - k_uptime_get());
		int err = receive_frame(transport, remaining, frame);

		if (err != 0) {
			return err;
		}
		if (frame->type == expected_type &&
		    frame->token == expected_token) {
			return 0;
		}
	}

	return -ETIMEDOUT;
}

static int serial_transfer_begin(void *context, uint32_t log_id,
				 uint32_t start_sector)
{
	struct flash_serial_transport *transport = context;
	uint8_t payload[8];

	transport->active_token = ++transport->token_counter;
	if (transport->active_token == 0U) {
		transport->active_token = ++transport->token_counter;
	}
	transport->active_ordinal = 0;
	store_u32_le(&payload[0], log_id);
	store_u32_le(&payload[4], start_sector);
	return send_frame(transport, FLASH_SERIAL_BEGIN,
			  transport->active_token, payload,
			  sizeof(payload));
}

static int serial_send_sector(void *context, uint32_t sector,
			      const struct flash_chunk *raw_sector)
{
	struct flash_serial_transport *transport = context;
	struct flash_serial_frame frame;
	uint8_t *payload = &transport->encoded[0];
	uint32_t ordinal = transport->active_ordinal;
	int err;

	store_u32_le(&payload[0], ordinal);
	store_u32_le(&payload[4], sector);
	memcpy(&payload[8], raw_sector, sizeof(*raw_sector));
	err = send_frame(transport, FLASH_SERIAL_SECTOR,
			 transport->active_token, payload,
			 (uint16_t)(8U + sizeof(*raw_sector)));
	if (err != 0) {
		return err;
	}

	err = wait_for_frame(transport, FLASH_SERIAL_SECTOR_ACK,
			     transport->active_token,
			     FLASH_SERIAL_FRAME_TIMEOUT_MS, &frame);
	if (err != 0 || frame.payload_length != 4U ||
	    load_u32_le(frame.payload) != ordinal) {
		return -EIO;
	}
	transport->active_ordinal++;
	return 0;
}

static bool summary_matches(const uint8_t *payload,
			    const struct flash_transfer_summary *summary)
{
	return load_u32_le(&payload[4]) == summary->log_id &&
	       load_u32_le(&payload[8]) == summary->start_sector &&
	       load_u32_le(&payload[12]) == summary->end_sector &&
	       load_u32_le(&payload[16]) == summary->sector_count &&
	       load_u32_le(&payload[20]) == summary->raw_crc;
}

static enum flash_transport_result
serial_transfer_finish(void *context,
		       const struct flash_transfer_summary *summary)
{
	struct flash_serial_transport *transport = context;
	struct flash_serial_frame frame;
	uint8_t payload[20];
	uint32_t disposition;
	int err;

	store_u32_le(&payload[0], summary->log_id);
	store_u32_le(&payload[4], summary->start_sector);
	store_u32_le(&payload[8], summary->end_sector);
	store_u32_le(&payload[12], summary->sector_count);
	store_u32_le(&payload[16], summary->raw_crc);
	err = send_frame(transport, FLASH_SERIAL_END,
			 transport->active_token, payload,
			 sizeof(payload));
	if (err != 0) {
		return FLASH_TRANSPORT_RETRY;
	}

	err = wait_for_frame(transport, FLASH_SERIAL_DISPOSITION,
			     transport->active_token,
			     FLASH_SERIAL_FRAME_TIMEOUT_MS, &frame);
	if (err != 0 || frame.payload_length != 24U ||
	    !summary_matches(frame.payload, summary)) {
		return FLASH_TRANSPORT_RETRY;
	}

	disposition = load_u32_le(&frame.payload[0]);
	if (disposition == FLASH_SERIAL_DISPOSITION_ERASE) {
		return FLASH_TRANSPORT_ERASE;
	}
	if (disposition == FLASH_SERIAL_DISPOSITION_DONE) {
		return FLASH_TRANSPORT_DONE;
	}
	return FLASH_TRANSPORT_RETRY;
}

const struct flash_transport_ops flash_serial_transport_ops = {
	.begin = serial_transfer_begin,
	.send_sector = serial_send_sector,
	.finish = serial_transfer_finish,
};

int flash_serial_transport_init(struct flash_serial_transport *transport,
				const struct device *uart,
				uint32_t sector_count)
{
	int err;

	if (transport == NULL || uart == NULL || !device_is_ready(uart) ||
	    sector_count < 3U) {
		return -EINVAL;
	}

	memset(transport, 0, sizeof(*transport));
	transport->uart = uart;
	transport->sector_count = sector_count;
	transport->token_counter = k_cycle_get_32();
	k_msgq_init(&transport->rx_queue, transport->rx_queue_buffer,
		      sizeof(transport->rx_queue_buffer[0]),
		      FLASH_SERIAL_RX_QUEUE_BYTES);
	k_sem_init(&transport->tx_done, 0, 1);
	err = uart_irq_callback_user_data_set(
		uart, serial_uart_callback, transport);
	if (err != 0) {
		return err;
	}

	/* The CDC ACM driver does not queue USB OUT transfers until RX is enabled. */
	uart_irq_rx_enable(uart);
	return 0;
}

static int send_info(struct flash_serial_transport *transport,
		     const struct flash_log *log)
{
	uint8_t payload[12];

	store_u32_le(&payload[0], FLASH_LOG_SECTOR_BYTES);
	store_u32_le(&payload[4], transport->sector_count);
	store_u32_le(&payload[8], flash_log_is_empty(log) ? 1U : 0U);
	return send_frame(transport, FLASH_SERIAL_INFO, 0U, payload,
			  sizeof(payload));
}

static void send_error(struct flash_serial_transport *transport,
		       enum flash_log_result result)
{
	uint8_t payload[4];

	store_u32_le(payload, (uint32_t)result);
	(void)send_frame(transport, FLASH_SERIAL_ERROR, 0U, payload,
			 sizeof(payload));
}

enum flash_serial_session_result
flash_serial_upload_session(struct flash_serial_transport *transport,
			    struct flash_log *log,
			    uint32_t hello_timeout_ms)
{
	struct flash_serial_frame frame;
	int err;

	if (transport == NULL || log == NULL ||
	    log->transport != &flash_serial_transport_ops) {
		return FLASH_SERIAL_SESSION_ERROR;
	}

	err = wait_for_frame(transport, FLASH_SERIAL_HELLO, 0U,
			     hello_timeout_ms, &frame);
	if (err != 0) {
		return FLASH_SERIAL_NO_HOST;
	}
	if (send_info(transport, log) != 0) {
		return FLASH_SERIAL_SESSION_ERROR;
	}

	while (true) {
		enum flash_log_result result;

		err = receive_frame(transport,
				    FLASH_SERIAL_FRAME_TIMEOUT_MS, &frame);
		if (err != 0) {
			return FLASH_SERIAL_SESSION_ERROR;
		}
		if (frame.type == FLASH_SERIAL_HELLO &&
		    frame.token == 0U) {
			if (send_info(transport, log) != 0) {
				return FLASH_SERIAL_SESSION_ERROR;
			}
			continue;
		}
		if (frame.type == FLASH_SERIAL_SESSION_DONE &&
		    frame.token == 0U) {
			return FLASH_SERIAL_SESSION_COMPLETE;
		}
		if (frame.type != FLASH_SERIAL_READ_NEXT ||
		    frame.token != 0U) {
			continue;
		}
		if (flash_log_is_empty(log)) {
			if (send_frame(transport, FLASH_SERIAL_EMPTY, 0U,
				       NULL, 0U) != 0) {
				return FLASH_SERIAL_SESSION_ERROR;
			}
			continue;
		}

		result = flash_log_read_one(log);
		if (result == FLASH_LOG_OK) {
			if (send_frame(transport,
				       FLASH_SERIAL_ERASE_COMPLETE,
				       transport->active_token,
				       NULL, 0U) != 0) {
				return FLASH_SERIAL_SESSION_ERROR;
			}
			continue;
		}
		if (result == FLASH_LOG_TRANSPORT_DONE) {
			return FLASH_SERIAL_SESSION_COMPLETE;
		}
		if (result == FLASH_LOG_TRANSPORT_ERROR) {
			/* The range remains intact for another READ_NEXT. */
			continue;
		}
		send_error(transport, result);
		return FLASH_SERIAL_SESSION_ERROR;
	}
}
```

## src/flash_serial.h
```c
#ifndef SUS_FLASH_SERIAL_H_
#define SUS_FLASH_SERIAL_H_

#include <stdint.h>

#include <zephyr/device.h>
#include <zephyr/kernel.h>
#include <zephyr/sys/atomic.h>

#include "flash.h"

#define FLASH_SERIAL_PROTOCOL_VERSION 1U
#define FLASH_SERIAL_MAX_DECODED_BYTES \
	(12U + 8U + FLASH_LOG_SECTOR_BYTES + 4U)
#define FLASH_SERIAL_MAX_ENCODED_BYTES \
	(FLASH_SERIAL_MAX_DECODED_BYTES + \
	 FLASH_SERIAL_MAX_DECODED_BYTES / 254U + 3U)
#define FLASH_SERIAL_RX_QUEUE_BYTES 256U

enum flash_serial_session_result {
	FLASH_SERIAL_NO_HOST,
	FLASH_SERIAL_SESSION_COMPLETE,
	FLASH_SERIAL_SESSION_ERROR,
};

struct flash_serial_transport {
	const struct device *uart;
	uint32_t sector_count;
	uint32_t token_counter;
	uint32_t active_token;
	uint32_t active_ordinal;
	struct k_msgq rx_queue;
	char rx_queue_buffer[FLASH_SERIAL_RX_QUEUE_BYTES];
	atomic_t rx_overflow;
	struct k_sem tx_done;
	const uint8_t *tx_data;
	size_t tx_length;
	size_t tx_offset;
	atomic_t tx_active;
	uint8_t decoded[FLASH_SERIAL_MAX_DECODED_BYTES];
	uint8_t encoded[FLASH_SERIAL_MAX_ENCODED_BYTES];
};

int flash_serial_transport_init(struct flash_serial_transport *transport,
				const struct device *uart,
				uint32_t sector_count);

enum flash_serial_session_result
flash_serial_upload_session(struct flash_serial_transport *transport,
			    struct flash_log *log,
			    uint32_t hello_timeout_ms);

extern const struct flash_transport_ops flash_serial_transport_ops;

#endif /* SUS_FLASH_SERIAL_H_ */
```

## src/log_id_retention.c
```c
#include "log_id_retention.h"

#include <errno.h>
#include <stddef.h>
#include <stdint.h>
#include <string.h>

#include <zephyr/device.h>
#include <zephyr/devicetree.h>
#include <zephyr/drivers/retained_mem.h>
#include <zephyr/sys/crc.h>

#define RETAINED_LOG_ID_MAGIC UINT32_C(0x4c535553)
#define RETAINED_LOG_ID_VERSION_LEGACY UINT32_C(1)
#define RETAINED_LOG_ID_VERSION UINT32_C(2)
#define RETAINED_LOG_STATE_CLEAN UINT32_C(0x434c454e)
#define RETAINED_LOG_STATE_DIRTY UINT32_C(0x44495254)

struct retained_log_id_legacy {
	uint32_t magic;
	uint32_t version;
	uint32_t next_log_id;
	uint32_t next_log_id_inverse;
	uint32_t crc;
};

struct retained_log_id {
	uint32_t magic;
	uint32_t version;
	uint32_t state;
	struct flash_log_checkpoint checkpoint;
	uint32_t next_log_id_inverse;
	uint32_t crc;
};

static const struct device *const retained_memory =
	DEVICE_DT_GET(DT_ALIAS(retainedmemdevice));

static uint32_t retained_log_id_crc(const struct retained_log_id *state)
{
	return crc32_ieee((const uint8_t *)state,
			  offsetof(struct retained_log_id, crc));
}

static uint32_t
retained_log_id_legacy_crc(const struct retained_log_id_legacy *state)
{
	return crc32_ieee((const uint8_t *)state,
			  offsetof(struct retained_log_id_legacy, crc));
}

static int retained_log_id_device_check(void)
{
	if (!device_is_ready(retained_memory)) {
		return -ENODEV;
	}
	if (retained_mem_size(retained_memory) <
	    (ssize_t)sizeof(struct retained_log_id)) {
		return -ENOSPC;
	}
	return 0;
}

int log_id_retention_load(struct retained_log_state *result)
{
	struct retained_log_id state;
	struct retained_log_id_legacy legacy;
	int err;

	if (result == NULL) {
		return -EINVAL;
	}

	err = retained_log_id_device_check();
	if (err != 0) {
		return err;
	}

	err = retained_mem_read(retained_memory, 0, (uint8_t *)&state,
				sizeof(state));
	if (err != 0) {
		return err;
	}
	memcpy(&legacy, &state, sizeof(legacy));

	if (legacy.magic == RETAINED_LOG_ID_MAGIC &&
	    legacy.version == RETAINED_LOG_ID_VERSION_LEGACY &&
	    legacy.next_log_id_inverse == ~legacy.next_log_id &&
	    legacy.crc == retained_log_id_legacy_crc(&legacy)) {
		result->checkpoint = (struct flash_log_checkpoint) {
			.next_log_id = legacy.next_log_id,
		};
		result->clean = false;
		return 0;
	}

	if (state.magic != RETAINED_LOG_ID_MAGIC ||
	    state.version != RETAINED_LOG_ID_VERSION ||
	    (state.state != RETAINED_LOG_STATE_CLEAN &&
	     state.state != RETAINED_LOG_STATE_DIRTY) ||
	    state.next_log_id_inverse != ~state.checkpoint.next_log_id ||
	    state.crc != retained_log_id_crc(&state)) {
		return -ENODATA;
	}

	result->checkpoint = state.checkpoint;
	result->clean = state.state == RETAINED_LOG_STATE_CLEAN;
	return 0;
}

int log_id_retention_store(const struct flash_log_checkpoint *checkpoint,
			   bool clean)
{
	struct retained_log_id state;
	int err;

	if (checkpoint == NULL) {
		return -EINVAL;
	}

	state = (struct retained_log_id) {
		.magic = RETAINED_LOG_ID_MAGIC,
		.version = RETAINED_LOG_ID_VERSION,
		.state = clean ? RETAINED_LOG_STATE_CLEAN :
				 RETAINED_LOG_STATE_DIRTY,
		.checkpoint = *checkpoint,
		.next_log_id_inverse = ~checkpoint->next_log_id,
	};
	err = retained_log_id_device_check();

	if (err != 0) {
		return err;
	}

	state.crc = retained_log_id_crc(&state);
	return retained_mem_write(retained_memory, 0,
				  (const uint8_t *)&state, sizeof(state));
}
```

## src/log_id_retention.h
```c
#ifndef SUS_LOG_ID_RETENTION_H_
#define SUS_LOG_ID_RETENTION_H_

#include <stdbool.h>

#include "flash.h"

struct retained_log_state {
	struct flash_log_checkpoint checkpoint;
	bool clean;
};

int log_id_retention_load(struct retained_log_state *state);
int log_id_retention_store(const struct flash_log_checkpoint *checkpoint,
			   bool clean);

#endif /* SUS_LOG_ID_RETENTION_H_ */
```

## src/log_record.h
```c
#ifndef SUS_LOG_RECORD_H_
#define SUS_LOG_RECORD_H_

#include <stddef.h>
#include <stdint.h>

/*
 * Binary-compatible with the ESP32 "dual_mag" LogRecord. The nRF52840 is
 * little-endian, matching the host's <II... format.
 */
struct __attribute__((packed)) sus_log_record {
	uint32_t timestamp_ms;
	uint32_t sequence;
	int16_t imu1_accel_mg[3];
	int16_t imu2_accel_mg[3];
	int16_t imu1_gyro_dps10[3];
	int16_t imu2_gyro_dps10[3];
	int16_t mmc5603_mg[3];
	int16_t lis3mdl_mg[3];
	uint16_t angle;
	int32_t temp_deci_c;
};

_Static_assert(sizeof(struct sus_log_record) == 50U,
	       "ESP-compatible log record must remain 50 bytes");
_Static_assert(offsetof(struct sus_log_record, sequence) == 4U,
	       "sequence offset must match the ESP format");
_Static_assert(offsetof(struct sus_log_record, imu1_accel_mg) == 8U,
	       "IMU1 acceleration offset must match the ESP format");
_Static_assert(offsetof(struct sus_log_record, imu2_accel_mg) == 14U,
	       "IMU2 acceleration offset must match the ESP format");
_Static_assert(offsetof(struct sus_log_record, imu1_gyro_dps10) == 20U,
	       "IMU1 gyro offset must match the ESP format");
_Static_assert(offsetof(struct sus_log_record, imu2_gyro_dps10) == 26U,
	       "IMU2 gyro offset must match the ESP format");
_Static_assert(offsetof(struct sus_log_record, mmc5603_mg) == 32U,
	       "MMC5603 offset must match the ESP format");
_Static_assert(offsetof(struct sus_log_record, lis3mdl_mg) == 38U,
	       "LIS3MDL offset must match the ESP format");
_Static_assert(offsetof(struct sus_log_record, angle) == 44U,
	       "angle offset must match the ESP format");
_Static_assert(offsetof(struct sus_log_record, temp_deci_c) == 46U,
	       "temperature offset must match the ESP format");

#endif /* SUS_LOG_RECORD_H_ */
```

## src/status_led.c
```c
#include "status_led.h"

#include <errno.h>
#include <stdbool.h>

#include <zephyr/device.h>
#include <zephyr/devicetree.h>
#include <zephyr/drivers/gpio.h>

static const struct gpio_dt_spec red_led =
	GPIO_DT_SPEC_GET(DT_ALIAS(led0), gpios);
static const struct gpio_dt_spec green_led =
	GPIO_DT_SPEC_GET(DT_ALIAS(led1), gpios);
static const struct gpio_dt_spec blue_led =
	GPIO_DT_SPEC_GET(DT_ALIAS(led2), gpios);

static bool status_led_ready;

int status_led_init(void)
{
	int err;

	if (!gpio_is_ready_dt(&red_led) ||
	    !gpio_is_ready_dt(&green_led) ||
	    !gpio_is_ready_dt(&blue_led)) {
		return -ENODEV;
	}

	err = gpio_pin_configure_dt(&red_led, GPIO_OUTPUT_INACTIVE);
	if (err != 0) {
		return err;
	}
	err = gpio_pin_configure_dt(&green_led, GPIO_OUTPUT_INACTIVE);
	if (err != 0) {
		return err;
	}
	err = gpio_pin_configure_dt(&blue_led, GPIO_OUTPUT_INACTIVE);
	if (err != 0) {
		return err;
	}

	status_led_ready = true;
	return 0;
}

void status_led_set(enum status_led_color color)
{
	bool red;
	bool green;
	bool blue;

	if (!status_led_ready) {
		return;
	}

	red = color == STATUS_LED_RED || color == STATUS_LED_YELLOW ||
	      color == STATUS_LED_PURPLE || color == STATUS_LED_WHITE;
	green = color == STATUS_LED_GREEN || color == STATUS_LED_YELLOW ||
		color == STATUS_LED_WHITE;
	blue = color == STATUS_LED_BLUE || color == STATUS_LED_PURPLE ||
	       color == STATUS_LED_WHITE;

	(void)gpio_pin_set_dt(&red_led, red ? 1 : 0);
	(void)gpio_pin_set_dt(&green_led, green ? 1 : 0);
	(void)gpio_pin_set_dt(&blue_led, blue ? 1 : 0);
}
```

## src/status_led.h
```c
#ifndef SUS_STATUS_LED_H_
#define SUS_STATUS_LED_H_

enum status_led_color {
	STATUS_LED_OFF,
	STATUS_LED_RED,
	STATUS_LED_GREEN,
	STATUS_LED_BLUE,
	STATUS_LED_YELLOW,
	STATUS_LED_PURPLE,
	STATUS_LED_WHITE,
};

int status_led_init(void);
void status_led_set(enum status_led_color color);

#endif /* SUS_STATUS_LED_H_ */
```
